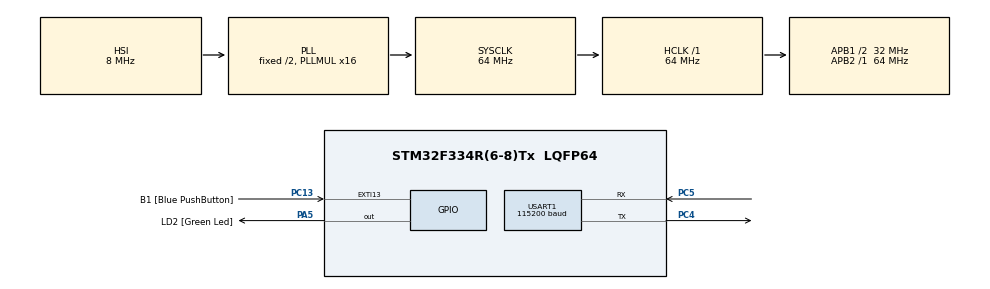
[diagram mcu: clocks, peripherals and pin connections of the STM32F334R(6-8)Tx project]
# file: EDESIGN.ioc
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Mcu.Family=STM32F3
Mcu.Name=STM32F334R(6-8)Tx
Mcu.Package=LQFP64
NVIC.PriorityGroup=NVIC_PRIORITYGROUP_0
NVIC.USART1_IRQn=true\:0\:0\:true\:true\:true\:1\:true
PA5.GPIO_Label=LD2 [Green Led]
PA5.Signal=GPIO_Output
PC13.GPIO_Label=B1 [Blue PushButton]
PC13.GPIO_ModeDefaultEXTI=GPIO_MODE_IT_FALLING
PC13.Signal=GPXTI13
PC14\ /\ OSC32_IN.Mode=LSE-External-Oscillator
PC14\ /\ OSC32_IN.Signal=RCC_OSC32_IN
PC15\ /\ OSC32_OUT.GPIO_Label=RCC_OSC32_OUT
PC15\ /\ OSC32_OUT.Mode=LSE-External-Oscillator
PC15\ /\ OSC32_OUT.Signal=RCC_OSC32_OUT
PC4.Mode=Asynchronous
PC4.Signal=USART1_TX
PC5.Mode=Asynchronous
PC5.Signal=USART1_RX
PF0\ /\ OSC_IN.Mode=HSE-External-Oscillator
PF0\ /\ OSC_IN.Signal=RCC_OSC_IN
PF1\ /\ OSC_OUT.Mode=HSE-External-Oscillator
PF1\ /\ OSC_OUT.Signal=RCC_OSC_OUT
ProjectManager.HeapSize=0x200
ProjectManager.StackSize=0x400
ProjectManager.TargetToolchain=TrueSTUDIO
RCC.AHBFreq_Value=64000000
RCC.APB1CLKDivider=RCC_HCLK_DIV2
RCC.APB1Freq_Value=32000000
RCC.APB1TimFreq_Value=64000000
RCC.APB2Freq_Value=64000000
RCC.APB2TimFreq_Value=64000000
RCC.CortexFreq_Value=64000000
RCC.FLatency-AdvancedSettings=FLASH_LATENCY_2
RCC.HCLKFreq_Value=64000000
RCC.HSE_VALUE=8000000
RCC.HSI_VALUE=8000000
RCC.PLLMUL=RCC_PLL_MUL16
RCC.SYSCLKFreq_VALUE=64000000
RCC.SYSCLKSourceVirtual=RCC_SYSCLKSOURCE_PLLCLK
RCC.Usart1ClockSelection=RCC_USART1CLKSOURCE_SYSCLK
USART1.BaudRate=115200
USART1.VirtualMode-Asynchronous=VM_ASYNC
USART1.WordLength=WORDLENGTH_8B
board=NUCLEO-F334R8

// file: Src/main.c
/**
  ******************************************************************************
  * File Name          : main.c
  * Description        : Main program body
  ******************************************************************************
  *
  * COPYRIGHT(c) 2018 STMicroelectronics
  *
  * Redistribution and use in source and binary forms, with or without modification,
  * are permitted provided that the following conditions are met:
  *   1. Redistributions of source code must retain the above copyright notice,
  *      this list of conditions and the following disclaimer.
  *   2. Redistributions in binary form must reproduce the above copyright notice,
  *      this list of conditions and the following disclaimer in the documentation
  *      and/or other materials provided with the distribution.
  *   3. Neither the name of STMicroelectronics nor the names of its contributors
  *      may be used to endorse or promote products derived from this software
  *      without specific prior written permission.
  *
  * THIS SOFTWARE IS PROVIDED BY THE COPYRIGHT HOLDERS AND CONTRIBUTORS "AS IS"
  * AND ANY EXPRESS OR IMPLIED WARRANTIES, INCLUDING, BUT NOT LIMITED TO, THE
  * IMPLIED WARRANTIES OF MERCHANTABILITY AND FITNESS FOR A PARTICULAR PURPOSE ARE
  * DISCLAIMED. IN NO EVENT SHALL THE COPYRIGHT HOLDER OR CONTRIBUTORS BE LIABLE
  * FOR ANY DIRECT, INDIRECT, INCIDENTAL, SPECIAL, EXEMPLARY, OR CONSEQUENTIAL
  * DAMAGES (INCLUDING, BUT NOT LIMITED TO, PROCUREMENT OF SUBSTITUTE GOODS OR
  * SERVICES; LOSS OF USE, DATA, OR PROFITS; OR BUSINESS INTERRUPTION) HOWEVER
  * CAUSED AND ON ANY THEORY OF LIABILITY, WHETHER IN CONTRACT, STRICT LIABILITY,
  * OR TORT (INCLUDING NEGLIGENCE OR OTHERWISE) ARISING IN ANY WAY OUT OF THE USE
  * OF THIS SOFTWARE, EVEN IF ADVISED OF THE POSSIBILITY OF SUCH DAMAGE.
  *
  ******************************************************************************
  */
#include "main.h"
#include "stm32f3xx_hal.h"

UART_HandleTypeDef huart1;

/* USER CODE BEGIN PV */
/* Private variables ---------------------------------------------------------*/

/* USER CODE END PV */

void SystemClock_Config(void);
void Error_Handler(void);
static void MX_GPIO_Init(void);
static void MX_USART1_UART_Init(void);
static void MX_NVIC_Init(void);

/* USER CODE BEGIN PFP */
/* Private function prototypes -----------------------------------------------*/

/* USER CODE END PFP */

/* USER CODE BEGIN 0 */

HAL_StatusTypeDef uart_status;
volatile uint8_t rx_flag = 0;

volatile uint8_t buffer[40];
uint8_t rx_buf;
volatile uint8_t uart_counter = 0;
volatile uint8_t* rx_buffer = buffer;

uint8_t tx[2] = {"y"};

uint32_t meep;

/* USER CODE END 0 */

int main(void)
{

  /* MCU Configuration----------------------------------------------------------*/

  /* Reset of all peripherals, Initializes the Flash interface and the Systick. */
  HAL_Init();

  /* Configure the system clock */
  SystemClock_Config();

  /* Initialize all configured peripherals */
  MX_GPIO_Init();
  MX_USART1_UART_Init();

  /* Initialize interrupts */
  MX_NVIC_Init();

  /* USER CODE BEGIN 2 */
  HAL_UART_Receive_IT(&huart1, &rx_buf, 1);
  /* USER CODE END 2 */

  /* Infinite loop */
  while (1)
  {

  /* USER CODE BEGIN 3 */

//	uart_status =

	  if (rx_flag == 1) {

		  rx_flag = 0;
		  HAL_UART_Transmit_IT(&huart1, &rx_buf, 1);
		  HAL_UART_Receive_IT(&huart1, &rx_buf, 1);

//	  			if(uart_counter == 0 && rx_buf == '$'){
//	  				buffer[uart_counter] = rx_buf;
//	  				uart_counter += 1;
//	  			}
//	  			else if(uart_counter != 0){
//	  				buffer[uart_counter] = rx_buf;
//	  				uart_counter += 1;
//	  			}
//	  			else if(uart_counter != 0 && buffer[uart_counter] ==  0xD && buffer[uart_counter -1] == 0xA ){
//	  				uart_counter = 0;

	  			}
  /* USER CODE END 3 */

}

/** System Clock Configuration
*/
void SystemClock_Config(void)
{

  RCC_OscInitTypeDef RCC_OscInitStruct;
  RCC_ClkInitTypeDef RCC_ClkInitStruct;
  RCC_PeriphCLKInitTypeDef PeriphClkInit;

    /**Initializes the CPU, AHB and APB busses clocks
    */
  RCC_OscInitStruct.OscillatorType = RCC_OSCILLATORTYPE_HSI;
  RCC_OscInitStruct.HSIState = RCC_HSI_ON;
  RCC_OscInitStruct.HSICalibrationValue = 16;
  RCC_OscInitStruct.PLL.PLLState = RCC_PLL_ON;
  RCC_OscInitStruct.PLL.PLLSource = RCC_PLLSOURCE_HSI;
  RCC_OscInitStruct.PLL.PLLMUL = RCC_PLL_MUL16;
  if (HAL_RCC_OscConfig(&RCC_OscInitStruct) != HAL_OK)
  {
    Error_Handler();
  }

    /**Initializes the CPU, AHB and APB busses clocks
    */
  RCC_ClkInitStruct.ClockType = RCC_CLOCKTYPE_HCLK|RCC_CLOCKTYPE_SYSCLK
                              |RCC_CLOCKTYPE_PCLK1|RCC_CLOCKTYPE_PCLK2;
  RCC_ClkInitStruct.SYSCLKSource = RCC_SYSCLKSOURCE_PLLCLK;
  RCC_ClkInitStruct.AHBCLKDivider = RCC_SYSCLK_DIV1;
  RCC_ClkInitStruct.APB1CLKDivider = RCC_HCLK_DIV2;
  RCC_ClkInitStruct.APB2CLKDivider = RCC_HCLK_DIV1;

  if (HAL_RCC_ClockConfig(&RCC_ClkInitStruct, FLASH_LATENCY_2) != HAL_OK)
  {
    Error_Handler();
  }

  PeriphClkInit.PeriphClockSelection = RCC_PERIPHCLK_USART1;
  PeriphClkInit.Usart1ClockSelection = RCC_USART1CLKSOURCE_SYSCLK;
  if (HAL_RCCEx_PeriphCLKConfig(&PeriphClkInit) != HAL_OK)
  {
    Error_Handler();
  }

    /**Configure the Systick interrupt time
    */
  HAL_SYSTICK_Config(HAL_RCC_GetHCLKFreq()/1000);

    /**Configure the Systick
    */
  HAL_SYSTICK_CLKSourceConfig(SYSTICK_CLKSOURCE_HCLK);

  /* SysTick_IRQn interrupt configuration */
  HAL_NVIC_SetPriority(SysTick_IRQn, 0, 0);
}

/** NVIC Configuration
*/
static void MX_NVIC_Init(void)
{
  /* USART1_IRQn interrupt configuration */
  HAL_NVIC_SetPriority(USART1_IRQn, 0, 0);
  HAL_NVIC_EnableIRQ(USART1_IRQn);
}

/* USART1 init function */
static void MX_USART1_UART_Init(void)
{

  huart1.Instance = USART1;
  huart1.Init.BaudRate = 115200;
  huart1.Init.WordLength = UART_WORDLENGTH_8B;
  huart1.Init.StopBits = UART_STOPBITS_1;
  huart1.Init.Parity = UART_PARITY_NONE;
  huart1.Init.Mode = UART_MODE_TX_RX;
  huart1.Init.HwFlowCtl = UART_HWCONTROL_NONE;
  huart1.Init.OverSampling = UART_OVERSAMPLING_16;
  huart1.Init.OneBitSampling = UART_ONE_BIT_SAMPLE_DISABLE;
  huart1.AdvancedInit.AdvFeatureInit = UART_ADVFEATURE_NO_INIT;
  if (HAL_UART_Init(&huart1) != HAL_OK)
  {
    Error_Handler();
  }

}

/** Configure pins as
        * Analog
        * Input
        * Output
        * EVENT_OUT
        * EXTI
*/
static void MX_GPIO_Init(void)
{

  GPIO_InitTypeDef GPIO_InitStruct;

  /* GPIO Ports Clock Enable */
  __HAL_RCC_GPIOC_CLK_ENABLE();
  __HAL_RCC_GPIOF_CLK_ENABLE();
  __HAL_RCC_GPIOA_CLK_ENABLE();

  /*Configure GPIO pin Output Level */
  HAL_GPIO_WritePin(LD2_GPIO_Port, LD2_Pin, GPIO_PIN_RESET);

  /*Configure GPIO pin : B1_Pin */
  GPIO_InitStruct.Pin = B1_Pin;
  GPIO_InitStruct.Mode = GPIO_MODE_IT_FALLING;
  GPIO_InitStruct.Pull = GPIO_NOPULL;
  HAL_GPIO_Init(B1_GPIO_Port, &GPIO_InitStruct);

  /*Configure GPIO pin : LD2_Pin */
  GPIO_InitStruct.Pin = LD2_Pin;
  GPIO_InitStruct.Mode = GPIO_MODE_OUTPUT_PP;
  GPIO_InitStruct.Pull = GPIO_NOPULL;
  GPIO_InitStruct.Speed = GPIO_SPEED_FREQ_LOW;
  HAL_GPIO_Init(LD2_GPIO_Port, &GPIO_InitStruct);

}

/* USER CODE BEGIN 4 */
//void HAL_UART_RxCpltCallback(UART_HandleTypeDef *huart){
//	rx_flag = 1;
//}

/* USER CODE END 4 */

void Error_Handler(void)
{
  while(1)
  {
  }
}

/************************ (C) COPYRIGHT STMicroelectronics *****END OF FILE****/
